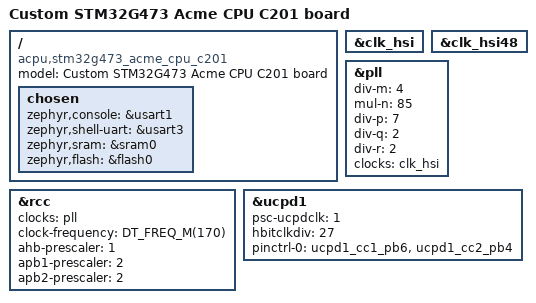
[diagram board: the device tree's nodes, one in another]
/*
 * Copyright (c) 2021 Acme CPU
 */

/dts-v1/;

#include <st/g4/stm32g473Xe.dtsi>
#include <st/g4/stm32g473_acpu.dtsi>
#include <../../modules/hal/stm32/dts/st/g4/stm32g473r(b-c-e)tx-pinctrl.dtsi>
#include <stm32g473_acme_cpu_c201/acpu_c201.dtsi>

/ {
	model = "Custom STM32G473 Acme CPU C201 board";
	compatible = "acpu,stm32g473_acme_cpu_c201";

	chosen {
	    zephyr,console = &usart1;
	    zephyr,shell-uart = &usart3;
	    zephyr,sram = &sram0;
	    zephyr,flash = &flash0;
	    /*zephyr,display = &st7789v2;*/
	};
};

&clk_hsi {
	status = "okay";
};

&clk_hsi48 {
	status = "okay";
};


&pll {
	div-m = <4>;
	mul-n = <85>;
	div-p = <7>;
	div-q = <2>;
	div-r = <2>;
	clocks = <&clk_hsi>;
	status = "okay";
};

&rcc {
	clocks = <&pll>;
	clock-frequency = <DT_FREQ_M(170)>;
	ahb-prescaler = <1>;
	apb1-prescaler = <2>;
	apb2-prescaler = <2>;
};

&ucpd1 {
	status = "okay";

	/*
	 * UCPD is fed directly from HSI which is @ 16MHz. The ucpd_clk goes to
	 * a prescaler who's output feeds the 'half-bit' divider which is used
	 * to generate clock for delay counters and BMC Rx/Tx blocks. The rx is
	 * designed to work in freq ranges of 6 <--> 18 MHz, however recommended
	 * range is 9 <--> 18 MHz.
	 *
	 *          +-------+ @ 16 MHz +-------+   @ ~600 kHz   +-----------+
	 * HSI ---->| /psc  |--------->| /hbit |--------------->| trans_cnt |
	 *          +-------+          +-------+   |            +-----------+
	 *                                         |            +-----------+
	 *                                         +----------->| ifrgap_cnt|
	 *                                                      +-----------+
	 * Requirements:
	 *   1. hbit_clk ~= 600 kHz: 16 MHz / 600 kHz = 26.67
	 *   2. tTransitionWindow - 12 to 20 uSec
	 *   3. tInterframGap - uSec
	 *
	 * hbit_clk = HSI_clk / 27 = 592.6 kHz = 1.687 uSec period
	 * tTransitionWindow = 1.687 uS * 8 = 13.5 uS
	 * tInterFrameGap = 1.687 uS * 17 = 28.68 uS
	 */
	psc-ucpdclk = <1>;
	hbitclkdiv = <27>;
	pinctrl-0 = <&ucpd1_cc1_pb6 &ucpd1_cc2_pb4>;
	pinctrl-names = "default";
};
